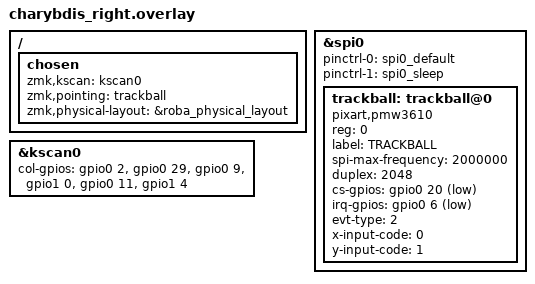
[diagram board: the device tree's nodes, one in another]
// config/boards/shields/charybdis_old/charybdis_right.overlay
// (dtsi の修正に合わせて chosen を修正)

#include "charybdis.dtsi"

/ {
    chosen {
        zmk,kscan = <&kscan0>;
        zmk,pointing = <&trackball>;
        // ↓ dtsi から移動させた、必須の行
        zmk,physical-layout = &roba_physical_layout; 
    };
};

// 1. kscan の「列」定義（あなたの設定）
&kscan0 {
	col-gpios
		= <&gpio0 2 (GPIO_ACTIVE_HIGH | GPIO_PULL_DOWN)>
		, <&gpio0 29 (GPIO_ACTIVE_HIGH | GPIO_PULL_DOWN)>
		, <&gpio0 9 (GPIO_ACTIVE_HIGH | GPIO_PULL_DOWN)>
		, <&gpio1 0 (GPIO_ACTIVE_HIGH | GPIO_PULL_DOWN)>
		, <&gpio0 11 (GPIO_ACTIVE_HIGH | GPIO_PULL_DOWN)>
		, <&gpio1 4 (GPIO_ACTIVE_HIGH | GPIO_PULL_DOWN)>
		;
};

// 2. SPIバスとトラックボールの完全な定義
&spi0 {
    // dtsi が修正されたため、これが今度こそ見つかるはず
    pinctrl-0 = <&spi0_default>;
    pinctrl-1 = <&spi0_sleep>;
    pinctrl-names = "default", "sleep";
    status = "okay"; 

    trackball: trackball@0 {
        compatible = "pixart,pmw3610";
        reg = <0>;
        label = "TRACKBALL";
        spi-max-frequency = <2000000>;
        duplex = <2048>;
        status = "okay"; 

        cs-gpios = <&gpio0 20 GPIO_ACTIVE_LOW>; 
        irq-gpios = <&gpio0 6 (GPIO_ACTIVE_LOW | GPIO_PULL_UP)>;
        evt-type = <2>;
        x-input-code = <0>;
        y-input-code = <1>;
    };
};
